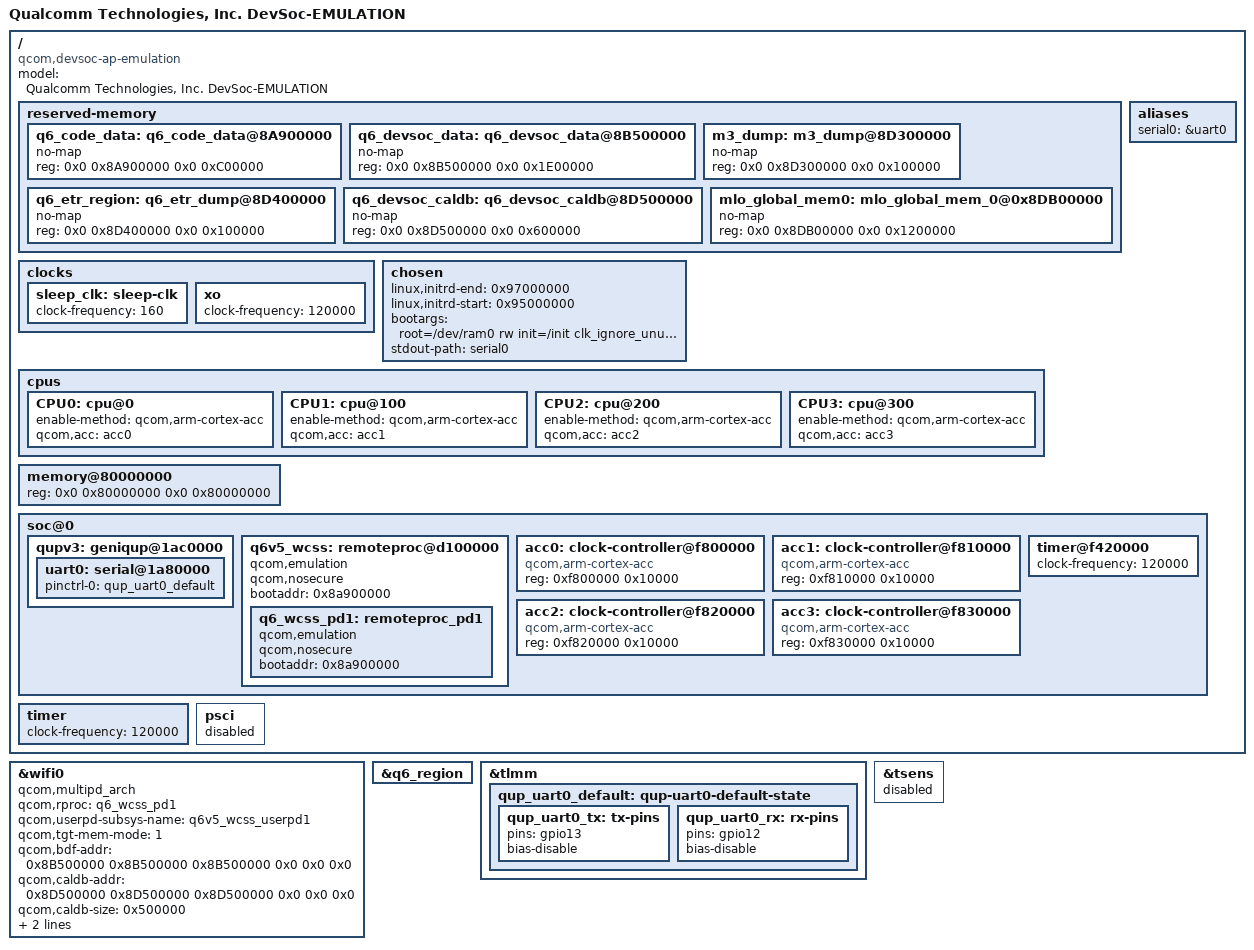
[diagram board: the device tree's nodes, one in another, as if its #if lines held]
// SPDX-License-Identifier: (GPL-2.0+ OR BSD-3-Clause)
/*
 * Dev SoC Emulation SSOC device tree source
 *
 * Copyright (c) 2020-2021 The Linux Foundation. All rights reserved.
 * Copyright (c) 2022-2023 Qualcomm Innovation Center, Inc. All rights reserved.
 */

/dts-v1/;

#include "ipq5424.dtsi"

/ {
	model = "Qualcomm Technologies, Inc. DevSoc-EMULATION";
	compatible = "qcom,devsoc-ap-emulation", "qcom,devsoc";

	/delete-node/ firmware;

	/*	  Layout for IPQ5424
	 * +==========+==============+========================+
	 * |         |              |                         |
	 * |  Region | Start Offset |          Size           |
	 * |         |              |                         |
	 * +---------+--------------+-------------------------+
	 * |   Q6    |              |                         |
	 * |  code/  |  0x8A900000  |          12MB           |
	 * |  data   |              |                         |
	 * +---------+--------------+-------------------------+
	 * | IPQ5424 |              |                         |
	 * |  data   |  0x8B500000  |          30MB           |
	 * +---------+--------------+-------------------------+
	 * | IPQ5424 |              |                         |
	 * | M3 Dump |  0x8D300000  |           1MB           |
	 * +---------+--------------+-------------------------+
	 * | IPQ5424 |              |                         |
	 * |  QDSS   |  0x8D400000  |           1MB           |
	 * +---------+--------------+-------------------------+
	 * | IPQ5424 |              |                         |
	 * |  CALDB  |  0x8D500000  |           6MB           |
	 * +---------+--------------+-------------------------+
	 * | IPQ5424 |              |                         |
	 * |  MLO    |  0x8DB00000  |          18MB           |
	 * +==================================================+
	 * |                                                  |
	 * |                                                  |
	 * |                                                  |
	 * |             Rest of memory for Linux             |
	 * |                                                  |
	 * |                                                  |
	 * |                                                  |
	 * +==================================================+
	 */

	reserved-memory {
		#address-cells = <2>;
		#size-cells = <2>;
		ranges;

		q6_code_data: q6_code_data@8A900000 {
			no-map;
			reg = <0x0 0x8A900000 0x0 0xC00000>;
		};

		q6_devsoc_data: q6_devsoc_data@8B500000 {
			no-map;
			reg = <0x0 0x8B500000 0x0 0x1E00000>;
		};

		m3_dump: m3_dump@8D300000 {
			no-map;
			reg = <0x0 0x8D300000 0x0 0x100000>;
		};

		q6_etr_region: q6_etr_dump@8D400000 {
			no-map;
			reg = <0x0 0x8D400000 0x0 0x100000>;
		};

		q6_devsoc_caldb: q6_devsoc_caldb@8D500000 {
			no-map;
			reg = <0x0 0x8D500000 0x0 0x600000>;
		};

		mlo_global_mem0: mlo_global_mem_0@0x8DB00000 {
			no-map;
			reg = <0x0 0x8DB00000 0x0 0x1200000>;
		};
        };

	/*Timer freq for rumi = timer freq / 200*/
	clocks {
		sleep_clk: sleep-clk {
			clock-frequency = <160>;
		};

		xo: xo {
			clock-frequency = <120000>;
		};
	};

	aliases {
		serial0 = &uart0;
	};

	chosen {
		linux,initrd-end = <0x97000000>;
		linux,initrd-start = <0x95000000>;
		bootargs = "root=/dev/ram0 rw init=/init clk_ignore_unused maxcpus=2";
		stdout-path = "serial0";
	};

	cpus: cpus {
		CPU0: cpu@0 {
			enable-method = "qcom,arm-cortex-acc";
			qcom,acc = <&acc0>;
		};

		CPU1: cpu@100 {
			enable-method = "qcom,arm-cortex-acc";
			qcom,acc = <&acc1>;
		};

		CPU2: cpu@200 {
			enable-method = "qcom,arm-cortex-acc";
			qcom,acc = <&acc2>;
		};

		CPU3: cpu@300 {
			enable-method = "qcom,arm-cortex-acc";
			qcom,acc = <&acc3>;
		};
	};

	memory@80000000 {
		reg = <0x0 0x80000000 0x0 0x80000000>;
	};

	soc@0 {
		qupv3: geniqup@1ac0000 {
			status = "okay";

			uart0: serial@1a80000 {
				pinctrl-0 = <&qup_uart0_default>;
				pinctrl-names = "default";
				status = "okay";
			};
		};

#ifdef __QCOM_NON_SECURE_PIL__
		q6v5_wcss: remoteproc@d100000 {
			qcom,emulation;
			qcom,nosecure;
			bootaddr = <0x8a900000>;
			status = "okay";
			q6_wcss_pd1: remoteproc_pd1 {
				qcom,emulation;
				qcom,nosecure;
				bootaddr = <0x8a900000>;
			};
		};
#endif

		acc0: clock-controller@f800000 {
			compatible = "qcom,arm-cortex-acc";
			reg = <0xf800000 0x10000>;
		};

		acc1: clock-controller@f810000 {
			compatible = "qcom,arm-cortex-acc";
			reg = <0xf810000 0x10000>;
		};

		acc2:clock-controller@f820000 {
			compatible = "qcom,arm-cortex-acc";
			reg = <0xf820000 0x10000>;
		};

		acc3:clock-controller@f830000 {
			compatible = "qcom,arm-cortex-acc";
			reg = <0xf830000 0x10000>;
		};

		/* Timer freq for rumi = timer freq / 200 */
		timer@f420000 {
			clock-frequency = <120000>;
		};
	};

	/* Timer freq for rumi = timer freq / 200 */
	timer {
		clock-frequency = <120000>;
	};

	psci {
		status = "disabled";
	};
};

&wifi0 {
	qcom,multipd_arch;
	qcom,rproc = <&q6_wcss_pd1>;
	qcom,userpd-subsys-name = "q6v5_wcss_userpd1";
	qcom,tgt-mem-mode = <1>;
	qcom,bdf-addr = <0x8B500000 0x8B500000 0x8B500000 0x0 0x0 0x0>;
	qcom,caldb-addr = <0x8D500000 0x8D500000 0x8D500000 0x0 0x0 0x0>;
	qcom,caldb-size = <0x500000>;
	memory-region = <&q6_devsoc_data>;
	qcom,board_id = <0x12>;
	status = "okay";
};

&q6_region {
	status = "okay";
};

&tlmm {
	qup_uart0_default: qup-uart0-default-state {
		qup_uart0_tx: tx-pins {
			pins = "gpio13";
			bias-disable;
		};

		qup_uart0_rx: rx-pins {
			pins = "gpio12";
			bias-disable;
		};
	};
};

&tsens {
	status = "disabled";
};
